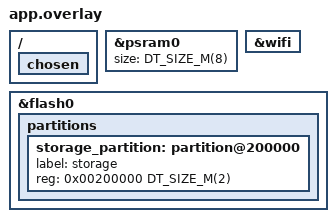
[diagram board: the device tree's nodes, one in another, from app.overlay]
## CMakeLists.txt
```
# SPDX-License-Identifier: Apache-2.0
cmake_minimum_required(VERSION 3.20.0)

set(ENV{ZEPHYR_BASE} "/home/alan/zephyr-projects/zephyr")
find_package(Zephyr REQUIRED HINTS $ENV{ZEPHYR_BASE})
project(espirate)

# Web Dashboard Generator: converts web/index.html -> web_dashboard.h
set(WEB_HTML_FILE ${CMAKE_CURRENT_SOURCE_DIR}/web/index.html)
set(GEN_WEB_HEADER ${CMAKE_CURRENT_BINARY_DIR}/include/web_dashboard.h)
set(GEN_WEB_SCRIPT ${CMAKE_CURRENT_SOURCE_DIR}/scripts/generate_web_dashboard.py)

# Generate at CMake configure time if not already present or out of date
execute_process(
  COMMAND ${PYTHON_EXECUTABLE} ${GEN_WEB_SCRIPT} ${WEB_HTML_FILE} ${GEN_WEB_HEADER}
)

# Custom command to regenerate during build whenever web/index.html or the generator changes
add_custom_command(
  OUTPUT ${GEN_WEB_HEADER}
  COMMAND ${PYTHON_EXECUTABLE} ${GEN_WEB_SCRIPT} ${WEB_HTML_FILE} ${GEN_WEB_HEADER}
  DEPENDS ${WEB_HTML_FILE} ${GEN_WEB_SCRIPT}
  COMMENT "Generating web_dashboard.h from ${WEB_HTML_FILE}"
  VERBATIM
)

# Custom target ensuring header is generated before any target compiles
add_custom_target(generate_web_dashboard DEPENDS ${GEN_WEB_HEADER})
add_dependencies(app generate_web_dashboard)

# How-To Guide Documentation Generator: converts doc/howto.md -> howto_doc.h
set(DOC_HOWTO_FILE ${CMAKE_CURRENT_SOURCE_DIR}/doc/howto.md)
set(GEN_DOC_HEADER ${CMAKE_CURRENT_BINARY_DIR}/include/howto_doc.h)
set(GEN_DOC_SCRIPT ${CMAKE_CURRENT_SOURCE_DIR}/scripts/generate_doc_header.py)

# Generate at CMake configure time if not already present or out of date
execute_process(
  COMMAND ${PYTHON_EXECUTABLE} ${GEN_DOC_SCRIPT} ${DOC_HOWTO_FILE} ${GEN_DOC_HEADER}
)

# Custom command to regenerate during build whenever doc/howto.md or the generator changes
add_custom_command(
  OUTPUT ${GEN_DOC_HEADER}
  COMMAND ${PYTHON_EXECUTABLE} ${GEN_DOC_SCRIPT} ${DOC_HOWTO_FILE} ${GEN_DOC_HEADER}
  DEPENDS ${DOC_HOWTO_FILE} ${GEN_DOC_SCRIPT}
  COMMENT "Generating howto_doc.h from ${DOC_HOWTO_FILE}"
  VERBATIM
)

# Custom target ensuring header is generated before any target compiles
add_custom_target(generate_doc_header DEPENDS ${GEN_DOC_HEADER})
add_dependencies(app generate_doc_header)

# Favicon Image Generator: converts web/favicon.png -> favicon_image.h
set(WEB_FAVICON_FILE ${CMAKE_CURRENT_SOURCE_DIR}/web/favicon.png)
set(GEN_FAVICON_HEADER ${CMAKE_CURRENT_BINARY_DIR}/include/favicon_image.h)
set(GEN_FAVICON_SCRIPT ${CMAKE_CURRENT_SOURCE_DIR}/scripts/generate_favicon_header.py)

# Generate at CMake configure time if not already present or out of date
execute_process(
  COMMAND ${PYTHON_EXECUTABLE} ${GEN_FAVICON_SCRIPT} ${WEB_FAVICON_FILE} ${GEN_FAVICON_HEADER}
)

# Custom command to regenerate during build whenever web/favicon.png or the generator changes
add_custom_command(
  OUTPUT ${GEN_FAVICON_HEADER}
  COMMAND ${PYTHON_EXECUTABLE} ${GEN_FAVICON_SCRIPT} ${WEB_FAVICON_FILE} ${GEN_FAVICON_HEADER}
  DEPENDS ${WEB_FAVICON_FILE} ${GEN_FAVICON_SCRIPT}
  COMMENT "Generating favicon_image.h from ${WEB_FAVICON_FILE}"
  VERBATIM
)

# Custom target ensuring header is generated before any target compiles
add_custom_target(generate_favicon_header DEPENDS ${GEN_FAVICON_HEADER})
add_dependencies(app generate_favicon_header)

# Include directories
target_include_directories(app PRIVATE
  ${CMAKE_CURRENT_SOURCE_DIR}/src
  ${CMAKE_CURRENT_SOURCE_DIR}/lua
  ${CMAKE_CURRENT_BINARY_DIR}/include
)

# Lua Engine Sources
set(LUA_SOURCES
  lua/lapi.c
  lua/lauxlib.c
  lua/lbaselib.c
  lua/lcode.c
  lua/lcorolib.c
  lua/lctype.c
  lua/ldblib.c
  lua/ldebug.c
  lua/ldo.c
  lua/ldump.c
  lua/lfunc.c
  lua/lgc.c
  lua/linit.c
  lua/liolib.c
  lua/llex.c
  lua/lmathlib.c
  lua/lmem.c
  lua/loadlib.c
  lua/lobject.c
  lua/lopcodes.c
  lua/loslib.c
  lua/lparser.c
  lua/lstate.c
  lua/lstring.c
  lua/lstrlib.c
  lua/ltable.c
  lua/ltablib.c
  lua/ltm.c
  lua/lundump.c
  lua/lutf8lib.c
  lua/lvm.c
  lua/lzio.c
)

# ESPirate Application Sources
target_sources(app PRIVATE
  src/main.c
  src/shell_commands.c
  src/lua_manager.c
  src/lua_worker.c
  src/fs_manager.c
  src/lua_gpio.c
  src/hw_gpio.c
  src/hw_pwm.c
  src/hw_i2c.c
  src/hw_spi.c
  src/wifi_manager.c
  src/captive_dns.c
  src/web_server.c
  src/posix_stubs.c
  src/setjmp.S
  ${GEN_WEB_HEADER}
  ${GEN_DOC_HEADER}
  ${LUA_SOURCES}
)

# Link math library
target_link_libraries(app PUBLIC -lm)

# Allow multiple definitions for standard libc/posix wrapper symbols
target_link_options(app PUBLIC "-Wl,--allow-multiple-definition")
```

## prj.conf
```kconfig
# ESPirate Zephyr Configuration
# Target: ESP32-S3 (DevKitM / DevKitC)

# Kernel Settings
CONFIG_MAIN_STACK_SIZE=8192
CONFIG_HEAP_MEM_POOL_SIZE=65536
CONFIG_SYSTEM_WORKQUEUE_STACK_SIZE=4096

# FPU & Standard C Library for Lua
CONFIG_FPU=y
CONFIG_FPU_SHARING=y
CONFIG_PICOLIBC=y
CONFIG_CBPRINTF_FP_SUPPORT=y

# Console & Shell (UART0 over USB CP2102 Bridge)
CONFIG_SERIAL=y
CONFIG_CONSOLE=y
CONFIG_UART_CONSOLE=y
CONFIG_SHELL=y
CONFIG_SHELL_BACKEND_SERIAL=y
CONFIG_SHELL_PROMPT_UART="ESPirate> "
CONFIG_SHELL_STACK_SIZE=8192
CONFIG_SHELL_CMD_BUFF_SIZE=512
CONFIG_SHELL_PRINTF_BUFF_SIZE=512
CONFIG_SHELL_WILDCARD=n

# Hardware control & Utilities
CONFIG_GPIO=y
CONFIG_REBOOT=y
CONFIG_LOG=y
CONFIG_LOG_MODE_IMMEDIATE=y
CONFIG_LOG_DEFAULT_LEVEL=3

# Flash & LittleFS Storage Subsystem
CONFIG_FLASH=y
CONFIG_FLASH_MAP=y
CONFIG_SPI_FLASH_SUPPORT_BOYA_CHIP=y
CONFIG_FILE_SYSTEM=y
CONFIG_FILE_SYSTEM_LITTLEFS=y
CONFIG_FILE_SYSTEM_SHELL=y
CONFIG_FILE_SYSTEM_MKFS=y
CONFIG_FS_LITTLEFS_LOOKAHEAD_SIZE=128

# PSRAM Configuration (8MB Embedded Octal PSRAM)
CONFIG_ESP_SPIRAM=y
CONFIG_ESP_SPIRAM_SIZE=8388608
CONFIG_SPIRAM_MODE_OCT=y
CONFIG_SPIRAM_TYPE_ESPPSRAM64=y
CONFIG_SPIRAM_SPEED_80M=y
CONFIG_ESP_SPIRAM_HEAP_SIZE=4194304

# Networking & BSD Sockets
CONFIG_NETWORKING=y
CONFIG_NET_IPV4=y
CONFIG_NET_IPV4_IGMP=y
CONFIG_NET_TCP=y
CONFIG_NET_UDP=y
CONFIG_NET_SOCKETS=y
CONFIG_NET_L2_ETHERNET=y
CONFIG_NET_L2_WIFI_MGMT=y
CONFIG_NET_MGMT=y
CONFIG_NET_MGMT_EVENT=y
CONFIG_NET_MGMT_EVENT_INFO=y
CONFIG_NET_CONNECTION_MANAGER=y
CONFIG_NET_CONNECTION_MANAGER_MONITOR_STACK_SIZE=1024
CONFIG_NET_CONFIG_AUTO_INIT=n
CONFIG_NET_IF_MAX_IPV4_COUNT=2
CONFIG_NET_IF_UNICAST_IPV4_ADDR_COUNT=4
CONFIG_NET_IF_MCAST_IPV4_ADDR_COUNT=4
CONFIG_NET_INTERFACE_NAME=y
CONFIG_NET_MAX_CONTEXTS=32
CONFIG_NET_MAX_CONN=32
CONFIG_NET_PKT_RX_COUNT=64
CONFIG_NET_PKT_TX_COUNT=48
CONFIG_NET_BUF_RX_COUNT=160
CONFIG_NET_BUF_TX_COUNT=160
CONFIG_NET_BUF_DATA_SIZE=1280
CONFIG_NET_TCP_TIME_WAIT_DELAY=250
CONFIG_NET_CONTEXT_RCVTIMEO=y
CONFIG_NET_CONTEXT_SNDTIMEO=y
CONFIG_ZVFS_POLL_MAX=32
CONFIG_NET_SOCKETS_SERVICE_STACK_SIZE=4096
CONFIG_NET_SOCKETS_SERVICE_THREAD_PRIO=6
CONFIG_NET_MGMT_EVENT_QUEUE_SIZE=16
CONFIG_NET_MGMT_EVENT_QUEUE_TIMEOUT=500
CONFIG_NET_LOG=y
CONFIG_MDNS_RESPONDER_LOG_LEVEL_INF=y
CONFIG_MDNS_RESPONDER_TTL=15
CONFIG_NET_SHELL=y
CONFIG_NET_STATISTICS=y
CONFIG_NET_STATISTICS_USER_API=y
CONFIG_NET_STATISTICS_IPV4=y
CONFIG_NET_STATISTICS_UDP=y
CONFIG_NET_STATISTICS_TCP=y
CONFIG_NET_STATISTICS_DNS=y

# DHCPv4 Client & Server
CONFIG_NET_DHCPV4=y
CONFIG_NET_DHCPV4_SERVER=y
CONFIG_NET_DHCPV4_SERVER_OPTION_ROUTER=y
CONFIG_NET_DHCPV4_SERVER_OPTION_DNS_ADDRESS="192.168.4.1"
CONFIG_NET_DHCPV4_SERVER_ADDR_COUNT=32
CONFIG_NET_DHCPV4_SERVER_ICMP_PROBE_TIMEOUT=0
CONFIG_NET_DHCPV4_SERVER_ADDR_DECLINE_TIME=60
CONFIG_NET_DHCPV4_SERVER_ADDR_LEASE_TIME=3600
CONFIG_NET_DHCPV4_SERVER_NAK_UNRECOGNIZED_REQUESTS=y
CONFIG_NET_DHCPV4_SERVER_LOG_LEVEL_DBG=y

# Hostname & mDNS Responder
CONFIG_NET_HOSTNAME_ENABLE=y
CONFIG_NET_HOSTNAME="espirate"
CONFIG_NET_HOSTNAME_DYNAMIC=y
CONFIG_NET_HOSTNAME_MAX_LEN=32
CONFIG_MDNS_RESPONDER=y

# Wi-Fi Driver (Exclusive AP or STA Mode)
CONFIG_WIFI=y
CONFIG_WIFI_ESP32=y
CONFIG_ESP32_WIFI_STA_AUTO_DHCPV4=n
CONFIG_ESP_WIFI_HEAP_SPIRAM=y
CONFIG_ESP32_WIFI_NET_ALLOC_SPIRAM=y
CONFIG_ESP32_WIFI_STA_SCAN_ALL=y
CONFIG_ESP32_WIFI_ENABLE_WPA3_SAE=y
CONFIG_ESP32_WIFI_WPA3_COMPATIBLE=y
CONFIG_WIFI_LOG_LEVEL_INF=y
CONFIG_NET_DHCPV4_LOG_LEVEL_DBG=y
CONFIG_ESP32_WIFI_DEBUG_PRINT=y
CONFIG_SHELL_LOG_LEVEL_DBG=y
CONFIG_LOG_CMDS=y

# Hardware Entropy Source
CONFIG_ENTROPY_GENERATOR=y
CONFIG_ENTROPY_ESP32_RNG=y
```

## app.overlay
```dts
/*
 * Copyright (c) 2026 Alan Mimms / ESPirate
 * SPDX-License-Identifier: Apache-2.0
 */

/ {
    chosen {
    };
};

/* 8MB Embedded PSRAM */
&psram0 {
    status = "okay";
    size = <DT_SIZE_M(8)>;
};

/* ESP32-S3 Wi-Fi Controller */
&wifi {
    status = "okay";
};

/* LittleFS Storage Partition baseline: 0x200000 (2MB offset).
 * On 4MB chip: 2MB LittleFS (0x200000 - 0x400000).
 * On 8MB chip: 6MB LittleFS (0x200000 - 0x800000, dynamically expanded at runtime).
 * On 16MB chip: 14MB LittleFS (0x200000 - 0x1000000, dynamically expanded at runtime).
 */
/delete-node/ &storage_partition;
/delete-node/ &slot1_partition;
/delete-node/ &slot0_appcpu_partition;
/delete-node/ &slot1_appcpu_partition;
/delete-node/ &slot0_lpcore_partition;
/delete-node/ &slot1_lpcore_partition;
/delete-node/ &scratch_partition;
/delete-node/ &coredump_partition;

&flash0 {
    partitions {
        storage_partition: partition@200000 {
            label = "storage";
            reg = <0x00200000 DT_SIZE_M(2)>;
        };
    };
};
```

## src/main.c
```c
/*
 * Copyright (c) 2026 Alan Mimms / ESPirate
 * SPDX-License-Identifier: Apache-2.0
 */

#include <zephyr/kernel.h>
#include <zephyr/logging/log.h>
#include <zephyr/version.h>
#include "shell_commands.h"
#include "lua_manager.h"
#include "lua_worker.h"
#include "fs_manager.h"
#include "wifi_manager.h"
#include "captive_dns.h"
#include "web_server.h"

LOG_MODULE_REGISTER(main, LOG_LEVEL_INF);

int main(void)
{
    LOG_INF("==================================================");
    LOG_INF("  ESPirate - Hardware Sequencing Architecture");
    LOG_INF("  Wi-Fi Dual-Mode (AP+STA), mDNS & Web Dashboard");
    LOG_INF("  Zephyr Kernel: %s", KERNEL_VERSION_STRING);
    LOG_INF("==================================================");

    /* Initialize LittleFS flash storage */
    int ret = fs_manager_init();
    if (ret != 0) {
        LOG_ERR("Failed to initialize LittleFS storage: %d", ret);
    }

    /* Initialize Lua VM and hardware subsystems */
    ret = lua_manager_init();
    if (ret != 0) {
        LOG_ERR("Failed to initialize Lua manager: %d", ret);
    }

    /* Start isolated Lua worker thread */
    ret = lua_worker_init();
    if (ret != 0) {
        LOG_ERR("Failed to initialize Lua worker: %d", ret);
    }

    /* Initialize Wi-Fi AP, STA, and dynamic hostname */
    ret = wifi_manager_init();
    if (ret != 0) {
        LOG_ERR("Failed to initialize Wi-Fi manager: %d", ret);
    }

    /* Start captive DNS responder on port 53 */
    ret = captive_dns_init();
    if (ret != 0) {
        LOG_ERR("Failed to initialize Captive DNS: %d", ret);
    }

    /* Start HTTP web server on port 80 */
    ret = web_server_init();
    if (ret != 0) {
        LOG_ERR("Failed to initialize Web server: %d", ret);
    }

    espirate_shell_init();

    LOG_INF("ESPirate shell ready on UART console.");
    LOG_INF("Soft-AP Dashboard : http://%s", wifi_manager_get_ip());
    LOG_INF("mDNS Local URL    : http://%s", wifi_manager_get_mdns_domain());
    LOG_INF("Pretend Internet  : %s",
            wifi_manager_get_fake_internet() ? "ENABLED (Android 204 active)" : "DISABLED");
    LOG_INF("Type 'help' or 'lua \"print(\\'hello\\')\"' to begin.");

    while (1) {
        k_sleep(K_SECONDS(30));
        LOG_DBG("Heartbeat tick - system alive (uptime: %lld ms)", k_uptime_get());
    }

    return 0;
}
```

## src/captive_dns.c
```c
/*
 * Copyright (c) 2026 Alan Mimms / ESPirate
 * SPDX-License-Identifier: Apache-2.0
 */

#include <zephyr/kernel.h>
#include <zephyr/logging/log.h>
#include <zephyr/net/socket.h>
#include <string.h>
#include <stdint.h>
#include "captive_dns.h"

LOG_MODULE_REGISTER(captive_dns, LOG_LEVEL_INF);

#define DNS_PORT 53
#define DNS_BUF_SIZE 512

K_THREAD_STACK_DEFINE(dns_thread_stack, 3072);
static struct k_thread dns_thread_data;
static bool s_enabled = true;
static int s_dns_sock = -1;

void captive_dns_set_enabled(bool enable)
{
    s_enabled = enable;
    LOG_INF("Captive DNS %s", enable ? "ENABLED (Pretend Internet ON)" : "DISABLED");
}

bool captive_dns_is_enabled(void)
{
    return s_enabled;
}

static void dns_thread_fn(void *p1, void *p2, void *p3)
{
    ARG_UNUSED(p1);
    ARG_UNUSED(p2);
    ARG_UNUSED(p3);

    /* Allow network interfaces to initialize */
    k_sleep(K_MSEC(1200));

    s_dns_sock = zsock_socket(AF_INET, SOCK_DGRAM, IPPROTO_UDP);
    if (s_dns_sock < 0) {
        LOG_ERR("Failed to create DNS UDP socket: %d", errno);
        return;
    }

    struct sockaddr_in bind_addr = {
        .sin_family = AF_INET,
        .sin_port = htons(DNS_PORT),
        .sin_addr.s_addr = htonl(INADDR_ANY),
    };

    if (zsock_bind(s_dns_sock, (struct sockaddr *)&bind_addr, sizeof(bind_addr)) < 0) {
        LOG_ERR("Failed to bind DNS socket to port %d: %d", DNS_PORT, errno);
        zsock_close(s_dns_sock);
        s_dns_sock = -1;
        return;
    }

    LOG_INF("Captive DNS responder active on UDP port %d", DNS_PORT);

    static uint8_t req_buf[DNS_BUF_SIZE];
    static uint8_t resp_buf[DNS_BUF_SIZE];

    while (1) {
        struct sockaddr_in client_addr;
        socklen_t client_len = sizeof(client_addr);

        ssize_t len = zsock_recvfrom(s_dns_sock, req_buf, sizeof(req_buf), 0,
                                     (struct sockaddr *)&client_addr, &client_len);
        if (len < 12) {
            continue;
        }

        if (!s_enabled) {
            continue;
        }

        /* Verify standard query (QR == 0) */
        if ((req_buf[2] & 0x80) != 0) {
            continue; /* Not a query */
        }

        /* Locate question section end */
        size_t pos = 12;
        while (pos < (size_t)len && req_buf[pos] != 0) {
            pos += 1 + req_buf[pos];
        }
        pos += 1; /* Skip trailing null byte of QNAME */
        pos += 4; /* Skip QTYPE (2 bytes) and QCLASS (2 bytes) */

        if (pos > (size_t)len || pos + 16 > sizeof(resp_buf)) {
            continue;
        }

        /* Build Response Header */
        memcpy(resp_buf, req_buf, pos);
        resp_buf[2] = 0x81; /* QR=1 (response), AA=1, RD=1 */
        resp_buf[3] = 0x80; /* RA=1, RCODE=0 (no error) */
        resp_buf[4] = 0x00; resp_buf[5] = 0x01; /* QDCOUNT = 1 */
        resp_buf[6] = 0x00; resp_buf[7] = 0x01; /* ANCOUNT = 1 */
        resp_buf[8] = 0x00; resp_buf[9] = 0x00; /* NSCOUNT = 0 */
        resp_buf[10] = 0x00; resp_buf[11] = 0x00; /* ARCOUNT = 0 */

        /* Append Answer Section (pointing to QNAME at offset 12) */
        resp_buf[pos++] = 0xc0; /* Pointer label */
        resp_buf[pos++] = 0x0c; /* Offset 12 */
        resp_buf[pos++] = 0x00; resp_buf[pos++] = 0x01; /* Type A */
        resp_buf[pos++] = 0x00; resp_buf[pos++] = 0x01; /* Class IN */
        resp_buf[pos++] = 0x00; resp_buf[pos++] = 0x00;
        resp_buf[pos++] = 0x00; resp_buf[pos++] = 0x3c; /* TTL: 60s */
        resp_buf[pos++] = 0x00; resp_buf[pos++] = 0x04; /* Length: 4 bytes */

        /* Target IPv4 address: 192.168.4.1 */
        resp_buf[pos++] = 192;
        resp_buf[pos++] = 168;
        resp_buf[pos++] = 4;
        resp_buf[pos++] = 1;

        zsock_sendto(s_dns_sock, resp_buf, pos, 0,
                     (struct sockaddr *)&client_addr, client_len);
    }
}

int captive_dns_init(void)
{
    k_thread_create(&dns_thread_data,
                    dns_thread_stack,
                    K_THREAD_STACK_SIZEOF(dns_thread_stack),
                    dns_thread_fn,
                    NULL, NULL, NULL,
                    7, 0, K_NO_WAIT);
    k_thread_name_set(&dns_thread_data, "captive_dns");
    return 0;
}
```

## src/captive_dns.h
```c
/*
 * Copyright (c) 2026 Alan Mimms / ESPirate
 * SPDX-License-Identifier: Apache-2.0
 */

#ifndef ESPIRATE_CAPTIVE_DNS_H_
#define ESPIRATE_CAPTIVE_DNS_H_

#include <stdbool.h>

#ifdef __cplusplus
extern "C" {
#endif

/**
 * @brief Initialize and start the captive DNS responder thread on UDP port 53.
 * @return 0 on success, negative error code on failure.
 */
int captive_dns_init(void);

/**
 * @brief Enable or disable captive DNS resolution (pretend internet).
 * @param enable true to resolve all DNS queries to 192.168.4.1, false to drop queries.
 */
void captive_dns_set_enabled(bool enable);

/**
 * @brief Check if captive DNS is currently enabled.
 * @return true if enabled, false otherwise.
 */
bool captive_dns_is_enabled(void);

#ifdef __cplusplus
}
#endif

#endif /* ESPIRATE_CAPTIVE_DNS_H_ */
```

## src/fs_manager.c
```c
/*
 * Copyright (c) 2026 Alan Mimms / ESPirate
 * SPDX-License-Identifier: Apache-2.0
 */

#include <zephyr/kernel.h>
#include <zephyr/device.h>
#include <zephyr/fs/fs.h>
#include <zephyr/fs/littlefs.h>
#include <zephyr/storage/flash_map.h>
#include <zephyr/logging/log.h>
#include <string.h>

#include "fs_manager.h"
#include "howto_doc.h"
#include "web_dashboard.h"
#include "favicon_image.h"

LOG_MODULE_REGISTER(fs_manager, LOG_LEVEL_INF);

FS_LITTLEFS_DECLARE_DEFAULT_CONFIG(storage_data);

static struct fs_mount_t espirate_lfs_mount = {
    .type = FS_LITTLEFS,
    .fs_data = &storage_data,
    .storage_dev = (void *)DT_FIXED_PARTITION_ID(DT_NODELABEL(storage_partition)),
    .mnt_point = ESPIRATE_FS_MOUNT_POINT,
};

static bool is_mounted = false;

#include <esp_err.h>
#include <esp_flash.h>
#include <esp_flash_internal.h>

extern const struct flash_area default_flash_map[];
extern const int flash_map_entries;
extern const struct flash_area *flash_map;

static struct flash_area s_dynamic_flash_map[16];
static size_t s_detected_partition_size = 0;
static uint32_t s_detected_chip_size = 0;

static void normalize_path(const char *in, char *out, size_t out_size)
{
    if (in[0] == '/') {
        strncpy(out, in, out_size - 1);
    } else {
        snprintf(out, out_size, "%s/%s", ESPIRATE_FS_MOUNT_POINT, in);
    }
    out[out_size - 1] = '\0';
}

int fs_manager_restore_docs(void)
{
    if (!is_mounted) {
        return -ENODEV;
    }
    int rc = fs_manager_write_file(ESPIRATE_FS_MOUNT_POINT "/howto.md",
                                   ESPIRATE_HOWTO_MD, ESPIRATE_HOWTO_MD_LEN);
    if (rc == 0) {
        LOG_INF("Restored /lfs/howto.md (%zu bytes) from firmware image", (size_t)ESPIRATE_HOWTO_MD_LEN);
    } else {
        LOG_ERR("Failed to restore /lfs/howto.md: %d", rc);
    }
    return rc;
}

int fs_manager_restore_web(void)
{
    if (!is_mounted) {
        return -ENODEV;
    }
    int rc = fs_manager_write_file(ESPIRATE_FS_MOUNT_POINT "/index.html",
                                   ESPIRATE_DASHBOARD_HTML, ESPIRATE_DASHBOARD_HTML_LEN);
    if (rc == 0) {
        LOG_INF("Restored /lfs/index.html (%zu bytes) from firmware image", (size_t)ESPIRATE_DASHBOARD_HTML_LEN);
    } else {
        LOG_ERR("Failed to restore /lfs/index.html: %d", rc);
    }
    return rc;
}

int fs_manager_restore_favicon(void)
{
    if (!is_mounted) {
        return -ENODEV;
    }
    int rc = fs_manager_write_file(ESPIRATE_FS_MOUNT_POINT "/favicon.png",
                                   ESPIRATE_FAVICON_PNG, ESPIRATE_FAVICON_PNG_LEN);
    if (rc == 0) {
        LOG_INF("Restored /lfs/favicon.png (%zu bytes) from firmware image", (size_t)ESPIRATE_FAVICON_PNG_LEN);
    } else {
        LOG_ERR("Failed to restore /lfs/favicon.png: %d", rc);
    }
    return rc;
}

int fs_manager_restore_all(void)
{
    if (!is_mounted) {
        return -ENODEV;
    }
    int ret = 0;
    int rc = fs_manager_restore_docs();
    if (rc != 0) ret = rc;
    rc = fs_manager_restore_web();
    if (rc != 0) ret = rc;
    rc = fs_manager_restore_favicon();
    if (rc != 0) ret = rc;
    return ret;
}

void fs_manager_create_default_files(void)
{
    if (!is_mounted) {
        return;
    }

    /* Write default demo script if it doesn't exist yet */
    struct fs_dirent dirent;
    if (fs_stat(ESPIRATE_FS_MOUNT_POINT "/demo.lua", &dirent) != 0) {
        const char *demo_code =
            "-- ESPirate LittleFS Demo Script\n"
            "print('========================================')\n"
            "print('Hello from /lfs/demo.lua!')\n"
            "print('Executing from persistent flash storage')\n"
            "print('Uptime ms:', sys.uptime())\n"
            "for i = 1, 3 do\n"
            "    print('  Iteration', i, 'running...')\n"
            "    sys.sleep(50)\n"
            "end\n"
            "print('Demo completed successfully.')\n"
            "print('========================================')\n";
        fs_manager_write_file(ESPIRATE_FS_MOUNT_POINT "/demo.lua", demo_code, strlen(demo_code));
        LOG_INF("Created default /lfs/demo.lua");
    }

    /* Write default howto.md documentation if it doesn't exist or size differs */
    if (fs_stat(ESPIRATE_FS_MOUNT_POINT "/howto.md", &dirent) != 0 ||
        dirent.size != (size_t)ESPIRATE_HOWTO_MD_LEN) {
        fs_manager_restore_docs();
    }

    /* Write default index.html dashboard if it doesn't exist or size differs */
    if (fs_stat(ESPIRATE_FS_MOUNT_POINT "/index.html", &dirent) != 0 ||
        dirent.size != (size_t)ESPIRATE_DASHBOARD_HTML_LEN) {
        fs_manager_restore_web();
    }

    /* Write default favicon.png if it doesn't exist or size differs */
    if (fs_stat(ESPIRATE_FS_MOUNT_POINT "/favicon.png", &dirent) != 0 ||
        dirent.size != (size_t)ESPIRATE_FAVICON_PNG_LEN) {
        fs_manager_restore_favicon();
    }
}

int fs_manager_init(void)
{
    if (is_mounted) {
        return 0;
    }

    esp_err_t ferr = esp_flash_init_default_chip();
    if (ferr != 0) {
        LOG_WRN("esp_flash_init_default_chip returned %d", ferr);
    }

    /* Detect actual physical SPI Flash size (4MB, 8MB, 16MB, etc.) */
    uint32_t chip_size = 0;
    esp_err_t sz_err = esp_flash_get_physical_size(NULL, &chip_size);
    if (sz_err != ESP_OK || chip_size == 0) {
        /* Fallback: read JEDEC ID directly (e.g. 0x684018 -> 1 << 0x18 = 16MB) */
        uint32_t flash_id = 0;
        if (esp_flash_read_id(NULL, &flash_id) == ESP_OK && flash_id > 0) {
            uint8_t size_code = flash_id & 0xFF;
            if (size_code >= 0x14 && size_code <= 0x21) { /* 1MB to 32MB */
                chip_size = 1U << size_code;
                LOG_INF("Derived physical flash size from JEDEC ID 0x%06x: %u MB (%u bytes)",
                        flash_id, chip_size / (1024 * 1024), chip_size);
            }
        }
    }

    if (chip_size > 0) {
        s_detected_chip_size = chip_size;
        /* Crucial: Update esp_flash_default_chip->size so ESP-IDF allows operations across full flash */
        if (esp_flash_default_chip != NULL) {
            esp_flash_default_chip->size = chip_size;
        }
        LOG_INF("Detected physical SPI flash size: %u MB (%u bytes)",
                chip_size / (1024 * 1024), chip_size);

        if (flash_map_entries <= ARRAY_SIZE(s_dynamic_flash_map)) {
            memcpy(s_dynamic_flash_map, default_flash_map,
                   flash_map_entries * sizeof(struct flash_area));

            uint8_t storage_id = (uint8_t)DT_FIXED_PARTITION_ID(DT_NODELABEL(storage_partition));
            for (int i = 0; i < flash_map_entries; i++) {
                if (s_dynamic_flash_map[i].fa_id == storage_id) {
                    off_t start_off = s_dynamic_flash_map[i].fa_off;
                    if ((uint32_t)start_off < chip_size) {
                        size_t dynamic_size = chip_size - start_off;
                        s_dynamic_flash_map[i].fa_size = dynamic_size;
                        s_detected_partition_size = dynamic_size;
                        LOG_INF("Dynamically adapted storage_partition: offset=0x%lx, size=%u MB (%zu bytes)",
                                (unsigned long)start_off,
                                (unsigned int)(dynamic_size / (1024 * 1024)),
                                dynamic_size);
                    }
                    break;
                }
            }
            flash_map = s_dynamic_flash_map;
        }
    } else {
        LOG_WRN("Physical flash size detection returned %d, using static DTS partition size", sz_err);
    }

    int rc = fs_mount(&espirate_lfs_mount);
    if (rc < 0) {
        LOG_WRN("LittleFS mount failed (%d); formatting blank/corrupt storage partition...", rc);
#if defined(CONFIG_FILE_SYSTEM_MKFS)
        rc = fs_mkfs(FS_LITTLEFS, (uintptr_t)DT_FIXED_PARTITION_ID(DT_NODELABEL(storage_partition)), NULL, 0);
        if (rc < 0) {
            LOG_ERR("fs_mkfs failed: %d", rc);
            return rc;
        }
        rc = fs_mount(&espirate_lfs_mount);
        if (rc < 0) {
            LOG_ERR("Failed to mount LittleFS after formatting: %d", rc);
            return rc;
        }
        LOG_INF("LittleFS partition formatted and mounted at %s", ESPIRATE_FS_MOUNT_POINT);
#else
        return rc;
#endif
    } else {
        /* Check if existing mounted filesystem size matches detected physical partition */
        struct fs_statvfs stat;
        if (fs_statvfs(ESPIRATE_FS_MOUNT_POINT, &stat) == 0 && s_detected_partition_size > 0) {
            size_t mounted_bytes = (size_t)stat.f_blocks * stat.f_frsize;
            if (mounted_bytes != s_detected_partition_size) {
                LOG_WRN("Mounted LittleFS capacity (%zu bytes) != partition size (%zu bytes). Auto-reformatting to full capacity...",
                        mounted_bytes, s_detected_partition_size);
                fs_unmount(&espirate_lfs_mount);
#if defined(CONFIG_FILE_SYSTEM_MKFS)
                rc = fs_mkfs(FS_LITTLEFS, (uintptr_t)DT_FIXED_PARTITION_ID(DT_NODELABEL(storage_partition)), NULL, 0);
                if (rc == 0) {
                    rc = fs_mount(&espirate_lfs_mount);
                }
#endif
            }
        }
    }

    is_mounted = true;
    LOG_INF("LittleFS mounted successfully at %s", ESPIRATE_FS_MOUNT_POINT);

    fs_manager_create_default_files();
    return 0;
}

bool fs_manager_is_mounted(void)
{
    return is_mounted;
}

int fs_manager_format(void)
{
    int rc;
    if (is_mounted) {
        rc = fs_unmount(&espirate_lfs_mount);
        if (rc < 0) {
            LOG_WRN("fs_unmount returned %d", rc);
        }
        is_mounted = false;
    }

#if defined(CONFIG_FILE_SYSTEM_MKFS)
    rc = fs_mkfs(FS_LITTLEFS, (uintptr_t)DT_FIXED_PARTITION_ID(DT_NODELABEL(storage_partition)), NULL, 0);
    if (rc < 0) {
        LOG_ERR("fs_mkfs failed: %d", rc);
        return rc;
    }
#endif

    rc = fs_mount(&espirate_lfs_mount);
    if (rc < 0) {
        LOG_ERR("fs_mount after format failed: %d", rc);
        return rc;
    }

    is_mounted = true;
    LOG_INF("LittleFS formatted and remounted at %s", ESPIRATE_FS_MOUNT_POINT);

    fs_manager_create_default_files();
    return 0;
}

int fs_manager_statvfs(size_t *total_bytes, size_t *free_bytes)
{
    if (!is_mounted) {
        return -ENODEV;
    }

    struct fs_statvfs stat;
    int rc = fs_statvfs(ESPIRATE_FS_MOUNT_POINT, &stat);
    if (rc < 0) {
        LOG_ERR("fs_statvfs failed: %d", rc);
        return rc;
    }

    if (total_bytes) {
        *total_bytes = (size_t)stat.f_blocks * stat.f_frsize;
    }
    if (free_bytes) {
        *free_bytes = (size_t)stat.f_bfree * stat.f_frsize;
    }

    return 0;
}

int fs_manager_write_file(const char *path, const void *data, size_t len)
{
    if (!is_mounted) {
        return -ENODEV;
    }

    char full_path[160];
    normalize_path(path, full_path, sizeof(full_path));

    struct fs_file_t file;
    fs_file_t_init(&file);

    int rc = fs_open(&file, full_path, FS_O_CREATE | FS_O_WRITE | FS_O_TRUNC);
    if (rc < 0) {
        LOG_ERR("Failed to open %s for writing: %d", full_path, rc);
        return rc;
    }

    ssize_t written = fs_write(&file, data, len);
    fs_close(&file);

    if (written < 0) {
        LOG_ERR("Failed to write to %s: %d", full_path, (int)written);
        return (int)written;
    }

    return 0;
}

int fs_manager_read_file(const char *path, void *buf, size_t buf_size, size_t *bytes_read)
{
    if (!is_mounted) {
        return -ENODEV;
    }

    char full_path[160];
    normalize_path(path, full_path, sizeof(full_path));

    struct fs_file_t file;
    fs_file_t_init(&file);

    int rc = fs_open(&file, full_path, FS_O_READ);
    if (rc < 0) {
        LOG_ERR("Failed to open %s for reading: %d", full_path, rc);
        return rc;
    }

    ssize_t read_bytes = fs_read(&file, buf, buf_size);
    fs_close(&file);

    if (read_bytes < 0) {
        LOG_ERR("Failed to read from %s: %d", full_path, (int)read_bytes);
        return (int)read_bytes;
    }

    if (bytes_read) {
        *bytes_read = (size_t)read_bytes;
    }

    return 0;
}

int fs_manager_delete_file(const char *path)
{
    if (!is_mounted) {
        return -ENODEV;
    }

    char full_path[160];
    normalize_path(path, full_path, sizeof(full_path));

    int rc = fs_unlink(full_path);
    if (rc != 0) {
        LOG_ERR("Failed to unlink %s: %d", full_path, rc);
    }
    return rc;
}

int fs_manager_rename_file(const char *old_path, const char *new_path)
{
    if (!is_mounted) {
        return -ENODEV;
    }

    char old_full[160];
    char new_full[160];
    normalize_path(old_path, old_full, sizeof(old_full));
    normalize_path(new_path, new_full, sizeof(new_full));

    int rc = fs_rename(old_full, new_full);
    if (rc != 0) {
        LOG_ERR("Failed to rename %s to %s: %d", old_full, new_full, rc);
    }
    return rc;
}

int fs_manager_list_files(fs_file_info_t *files, size_t max_files, size_t *count)
{
    if (!is_mounted) {
        return -ENODEV;
    }

    struct fs_dir_t dir;
    fs_dir_t_init(&dir);

    int rc = fs_opendir(&dir, ESPIRATE_FS_MOUNT_POINT);
    if (rc != 0) {
        LOG_ERR("Failed to opendir %s: %d", ESPIRATE_FS_MOUNT_POINT, rc);
        return rc;
    }

    size_t n = 0;
    struct fs_dirent entry;
    while (fs_readdir(&dir, &entry) == 0 && entry.name[0] != 0) {
        if (entry.type == FS_DIR_ENTRY_FILE) {
            if (files && n < max_files) {
                strncpy(files[n].name, entry.name, sizeof(files[n].name) - 1);
                files[n].name[sizeof(files[n].name) - 1] = '\0';
                files[n].size = entry.size;
            }
            n++;
        }
    }
    fs_closedir(&dir);

    if (count) {
        *count = n;
    }
    return 0;
}

uint32_t fs_manager_get_chip_size(void)
{
    return s_detected_chip_size;
}

size_t fs_manager_get_partition_size(void)
{
    return s_detected_partition_size;
}
```

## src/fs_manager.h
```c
/*
 * Copyright (c) 2026 Alan Mimms / ESPirate
 * SPDX-License-Identifier: Apache-2.0
 */

#ifndef ESPIRATE_FS_MANAGER_H_
#define ESPIRATE_FS_MANAGER_H_

#include <stddef.h>
#include <stdbool.h>

#ifdef __cplusplus
extern "C" {
#endif

#define ESPIRATE_FS_MOUNT_POINT "/lfs"

typedef struct {
    char name[64];
    size_t size;
} fs_file_info_t;

/**
 * @brief Initialize and mount the LittleFS partition at /lfs.
 * If mounting fails (e.g. on fresh chip), auto-formats the partition.
 * @return 0 on success, negative error code on failure.
 */
int fs_manager_init(void);

/**
 * @brief Check if the LittleFS partition is currently mounted.
 * @return true if mounted, false otherwise.
 */
bool fs_manager_is_mounted(void);

/**
 * @brief Reformat the LittleFS partition and recreate default files.
 * @return 0 on success, negative error code on failure.
 */
int fs_manager_format(void);

/**
 * @brief Get filesystem capacity and free space statistics.
 * @param total_bytes Pointer to store total capacity in bytes.
 * @param free_bytes Pointer to store free space in bytes.
 * @return 0 on success, negative error code on failure.
 */
int fs_manager_statvfs(size_t *total_bytes, size_t *free_bytes);

/**
 * @brief Write data to a file in LittleFS.
 * @param path Full file path (e.g. "/lfs/test.lua").
 * @param data Buffer containing file content.
 * @param len Length of data in bytes.
 * @return 0 on success, negative error code on failure.
 */
int fs_manager_write_file(const char *path, const void *data, size_t len);

/**
 * @brief Read data from a file in LittleFS.
 * @param path Full file path.
 * @param buf Output buffer.
 * @param buf_size Size of output buffer.
 * @param bytes_read Pointer to store actual bytes read (optional).
 * @return 0 on success, negative error code on failure.
 */
int fs_manager_read_file(const char *path, void *buf, size_t buf_size, size_t *bytes_read);

/**
 * @brief Delete (unlink) a file in LittleFS.
 * @param path File path or filename (e.g. "test.lua" or "/lfs/test.lua").
 * @return 0 on success, negative error code on failure.
 */
int fs_manager_delete_file(const char *path);

/**
 * @brief Rename a file in LittleFS.
 * @param old_path Current path or filename.
 * @param new_path Target path or filename.
 * @return 0 on success, negative error code on failure.
 */
int fs_manager_rename_file(const char *old_path, const char *new_path);

/**
 * @brief List files in LittleFS mount point.
 * @param files Buffer to store file info structures (may be NULL if max_files is 0).
 * @param max_files Maximum number of entries to store.
 * @param count Pointer to receive actual total count found.
 * @return 0 on success, negative error code on failure.
 */
int fs_manager_list_files(fs_file_info_t *files, size_t max_files, size_t *count);

/**
 * @brief Ensure default system files exist (e.g. /lfs/demo.lua and /lfs/howto.md).
 */
void fs_manager_create_default_files(void);

/**
 * @brief Force restore /lfs/howto.md from compiled-in firmware documentation.
 * @return 0 on success, negative error code on failure.
 */
int fs_manager_restore_docs(void);

/**
 * @brief Force restore /lfs/index.html from compiled-in firmware dashboard.
 * @return 0 on success, negative error code on failure.
 */
int fs_manager_restore_web(void);

/**
 * @brief Force restore /lfs/favicon.png from compiled-in firmware image.
 * @return 0 on success, negative error code on failure.
 */
int fs_manager_restore_favicon(void);

/**
 * @brief Force restore all default files (demo.lua, howto.md, index.html, favicon.png).
 * @return 0 on success, negative error code on failure.
 */
int fs_manager_restore_all(void);

/**
 * @brief Get detected physical SPI flash chip size in bytes.
 * @return Detected physical size in bytes (e.g. 16777216 for 16MB), or 0 if undetected.
 */
uint32_t fs_manager_get_chip_size(void);

/**
 * @brief Get dynamically adapted LittleFS partition size in bytes.
 * @return Partition size in bytes, or 0 if undetected.
 */
size_t fs_manager_get_partition_size(void);

#ifdef __cplusplus
}
#endif

#endif /* ESPIRATE_FS_MANAGER_H_ */
```

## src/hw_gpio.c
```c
/*
 * Copyright (c) 2026 Alan Mimms / ESPirate
 * SPDX-License-Identifier: Apache-2.0
 */

#include <zephyr/kernel.h>
#include <zephyr/device.h>
#include <zephyr/drivers/gpio.h>
#include <zephyr/logging/log.h>
#include <string.h>
#include <stdio.h>

#include <esp_rom_gpio.h>
#include <soc/gpio_sig_map.h>

#include "hw_gpio.h"

LOG_MODULE_REGISTER(hw_gpio, LOG_LEVEL_INF);

static const struct device *gpio0_dev = DEVICE_DT_GET(DT_NODELABEL(gpio0));
static const struct device *gpio1_dev = DEVICE_DT_GET(DT_NODELABEL(gpio1));

static gpio_flags_t s_pin_flags[49] = {0};
static int s_pin_out_sig[49] = {0};
static int s_pin_in_sig[49] = {0};

int hw_gpio_init(void)
{
    if (!device_is_ready(gpio0_dev)) {
        LOG_WRN("gpio0 device not ready");
    }
    if (!device_is_ready(gpio1_dev)) {
        LOG_WRN("gpio1 device not ready");
    }
    for (int i = 0; i < 49; i++) {
        s_pin_flags[i] = GPIO_DISCONNECTED;
        s_pin_out_sig[i] = SIG_GPIO_OUT_IDX;
        s_pin_in_sig[i] = -1;
    }
    return 0;
}

int hw_gpio_check_safety(int pin, const char **reason)
{
    if (pin < 0 || pin > 48) {
        if (reason) *reason = "out of range (0..48)";
        return -EINVAL;
    }
    if (pin >= 22 && pin <= 25) {
        if (reason) *reason = "not bonded on ESP32-S3 silicon";
        return -EINVAL;
    }
    if (pin == 19 || pin == 20) {
        if (reason) *reason = "reserved for native USB OTG console (CDC-ACM)";
        return -EPERM;
    }
    if (pin >= 26 && pin <= 32) {
        if (reason) *reason = "reserved for Octal SPI Flash/PSRAM bus";
        return -EPERM;
    }
    if (pin >= 33 && pin <= 37) {
        if (reason) *reason = "reserved for Octal PSRAM data lines";
        return -EPERM;
    }
    return 0;
}

static int get_gpio_port_and_pin(int pin, const struct device **dev_out, gpio_pin_t *pin_out)
{
    const char *reason = NULL;
    int ret = hw_gpio_check_safety(pin, &reason);
    if (ret != 0) {
        return ret;
    }
    if (pin < 32) {
        *dev_out = gpio0_dev;
        *pin_out = (gpio_pin_t)pin;
    } else {
        *dev_out = gpio1_dev;
        *pin_out = (gpio_pin_t)(pin - 32);
    }
    if (!device_is_ready(*dev_out)) {
        return -ENODEV;
    }
    return 0;
}

int hw_gpio_mode(int pin, const char *mode, const char *pull)
{
    if (!mode) return -EINVAL;

    const struct device *dev;
    gpio_pin_t pin_idx;
    int ret = get_gpio_port_and_pin(pin, &dev, &pin_idx);
    if (ret != 0) return ret;

    gpio_flags_t flags = GPIO_DISCONNECTED;
    if (strcmp(mode, "out") == 0 || strcmp(mode, "output") == 0) {
        flags = GPIO_OUTPUT | GPIO_INPUT;
    } else if (strcmp(mode, "in") == 0 || strcmp(mode, "input") == 0) {
        flags = GPIO_INPUT;
    } else if (strcmp(mode, "in_pullup") == 0 || strcmp(mode, "pullup") == 0) {
        flags = GPIO_INPUT | GPIO_PULL_UP;
    } else if (strcmp(mode, "in_pulldown") == 0 || strcmp(mode, "pulldown") == 0) {
        flags = GPIO_INPUT | GPIO_PULL_DOWN;
    } else if (strcmp(mode, "out_pullup") == 0) {
        flags = GPIO_OUTPUT | GPIO_INPUT | GPIO_PULL_UP;
    } else if (strcmp(mode, "out_pulldown") == 0) {
        flags = GPIO_OUTPUT | GPIO_INPUT | GPIO_PULL_DOWN;
    } else if (strcmp(mode, "open_drain") == 0 || strcmp(mode, "od") == 0) {
        flags = GPIO_OUTPUT | GPIO_INPUT | GPIO_OPEN_DRAIN;
    } else if (strcmp(mode, "open_drain_pullup") == 0 || strcmp(mode, "od_pullup") == 0) {
        flags = GPIO_OUTPUT | GPIO_INPUT | GPIO_OPEN_DRAIN | GPIO_PULL_UP;
    } else if (strcmp(mode, "tristate") == 0 || strcmp(mode, "hiz") == 0 ||
               strcmp(mode, "hi_z") == 0 || strcmp(mode, "disconnected") == 0 ||
               strcmp(mode, "none") == 0) {
        flags = GPIO_DISCONNECTED;
    } else {
        return -EINVAL;
    }

    if (pull) {
        flags &= ~(GPIO_PULL_UP | GPIO_PULL_DOWN);
        if (strcmp(pull, "up") == 0 || strcmp(pull, "pullup") == 0) {
            flags |= GPIO_PULL_UP;
        } else if (strcmp(pull, "down") == 0 || strcmp(pull, "pulldown") == 0) {
            flags |= GPIO_PULL_DOWN;
        } else if (strcmp(pull, "none") == 0 || strcmp(pull, "floating") == 0 || strcmp(pull, "off") == 0) {
            /* clear pulls */
        } else {
            return -EINVAL;
        }
    }

    esp_rom_gpio_pad_select_gpio((uint32_t)pin);
    ret = gpio_pin_configure(dev, pin_idx, flags);
    if (ret != 0) return ret;

    s_pin_flags[pin] = flags;
    return 0;
}

int hw_gpio_pull(int pin, const char *pull)
{
    if (!pull) return -EINVAL;

    const struct device *dev;
    gpio_pin_t pin_idx;
    int ret = get_gpio_port_and_pin(pin, &dev, &pin_idx);
    if (ret != 0) return ret;

    gpio_flags_t flags = s_pin_flags[pin];
    if (flags == GPIO_DISCONNECTED && (flags & (GPIO_INPUT | GPIO_OUTPUT)) == 0) {
        flags = GPIO_INPUT;
    }

    flags &= ~(GPIO_PULL_UP | GPIO_PULL_DOWN);
    if (strcmp(pull, "up") == 0 || strcmp(pull, "pullup") == 0) {
        flags |= GPIO_PULL_UP;
    } else if (strcmp(pull, "down") == 0 || strcmp(pull, "pulldown") == 0) {
        flags |= GPIO_PULL_DOWN;
    } else if (strcmp(pull, "none") == 0 || strcmp(pull, "floating") == 0 || strcmp(pull, "off") == 0) {
        /* clear pulls */
    } else {
        return -EINVAL;
    }

    ret = gpio_pin_configure(dev, pin_idx, flags);
    if (ret != 0) return ret;

    s_pin_flags[pin] = flags;
    return 0;
}

int hw_gpio_tristate(int pin)
{
    const struct device *dev;
    gpio_pin_t pin_idx;
    int ret = get_gpio_port_and_pin(pin, &dev, &pin_idx);
    if (ret != 0) return ret;

    esp_rom_gpio_pad_select_gpio((uint32_t)pin);
    ret = gpio_pin_configure(dev, pin_idx, GPIO_DISCONNECTED);
    if (ret != 0) return ret;

    s_pin_flags[pin] = GPIO_DISCONNECTED;
    return 0;
}

int hw_gpio_write(int pin, int val)
{
    const struct device *dev;
    gpio_pin_t pin_idx;
    int ret = get_gpio_port_and_pin(pin, &dev, &pin_idx);
    if (ret != 0) return ret;

    /* Ensure output mode if currently disconnected */
    if ((s_pin_flags[pin] & GPIO_OUTPUT) == 0) {
        hw_gpio_mode(pin, "out", NULL);
    }

    return gpio_pin_set(dev, pin_idx, val ? 1 : 0);
}

int hw_gpio_read(int pin)
{
    const struct device *dev;
    gpio_pin_t pin_idx;
    int ret = get_gpio_port_and_pin(pin, &dev, &pin_idx);
    if (ret != 0) return ret;

    /* Ensure input buffer is active if currently disconnected */
    if ((s_pin_flags[pin] & GPIO_INPUT) == 0) {
        hw_gpio_mode(pin, "in", NULL);
    }

    return gpio_pin_get(dev, pin_idx);
}

int hw_gpio_toggle(int pin)
{
    const struct device *dev;
    gpio_pin_t pin_idx;
    int ret = get_gpio_port_and_pin(pin, &dev, &pin_idx);
    if (ret != 0) return ret;

    if ((s_pin_flags[pin] & GPIO_OUTPUT) == 0) {
        hw_gpio_mode(pin, "out", NULL);
    }

    return gpio_pin_toggle(dev, pin_idx);
}

int hw_gpio_high(int pin)
{
    return hw_gpio_write(pin, 1);
}

int hw_gpio_low(int pin)
{
    return hw_gpio_write(pin, 0);
}

int hw_gpio_drive(int pin, int ma)
{
    const char *reason = NULL;
    int ret = hw_gpio_check_safety(pin, &reason);
    if (ret != 0) return ret;

    uint32_t drv = 2; /* default 20mA */
    if (ma == 5 || ma == 0) drv = 0;
    else if (ma == 10 || ma == 1) drv = 1;
    else if (ma == 20 || ma == 2) drv = 2;
    else if (ma == 40 || ma == 3) drv = 3;
    else return -EINVAL;

    esp_rom_gpio_pad_set_drv((uint32_t)pin, drv);
    return 0;
}

int hw_gpio_get_info(int pin, hw_gpio_info_t *info)
{
    if (!info || pin < 0 || pin > 48) return -EINVAL;

    info->pin = pin;
    info->valid = (pin < 22 || pin > 25);
    info->reserved = (!info->valid || pin == 19 || pin == 20 || (pin >= 26 && pin <= 37));
    info->input = (info->valid && !info->reserved);
    info->output = (info->valid && !info->reserved);
    info->pullup = (info->valid && !info->reserved);
    info->pulldown = (info->valid && !info->reserved);

    static char adc_buf[16];
    if (pin >= 1 && pin <= 10) {
        snprintf(adc_buf, sizeof(adc_buf), "ADC1_CH%d", pin - 1);
        info->adc_name = adc_buf;
        info->analog = !info->reserved;
    } else if (pin >= 11 && pin <= 20) {
        snprintf(adc_buf, sizeof(adc_buf), "ADC2_CH%d", pin - 11);
        info->adc_name = adc_buf;
        info->analog = !info->reserved;
    } else {
        info->adc_name = NULL;
        info->analog = false;
    }

    if (!info->valid) {
        info->desc = "Not bonded on ESP32-S3 silicon";
    } else if (pin == 0) {
        info->desc = "Strapping Pin (BOOT button)";
    } else if (pin == 19) {
        info->desc = "Reserved: Native USB OTG D- (Console)";
    } else if (pin == 20) {
        info->desc = "Reserved: Native USB OTG D+ (Console)";
    } else if (pin >= 26 && pin <= 32) {
        info->desc = "Reserved: Octal SPI Flash / PSRAM";
    } else if (pin >= 33 && pin <= 37) {
        info->desc = "Reserved: Octal PSRAM data lines";
    } else if (pin == 43) {
        info->desc = "UART0 TXD (Console UART)";
    } else if (pin == 44) {
        info->desc = "UART0 RXD (Console UART)";
    } else if (pin == 45) {
        info->desc = "Strapping Pin (VDD_SPI voltage)";
    } else if (pin == 46) {
        info->desc = "Strapping Pin (Boot Mode / ROM log)";
    } else {
        info->desc = "General Purpose I/O";
    }

    return 0;
}

int hw_gpio_get_state(int pin, char *mode_buf, size_t mode_size, int *level)
{
    const char *reason = NULL;
    int ret = hw_gpio_check_safety(pin, &reason);
    if (ret != 0) {
        if (mode_buf && mode_size > 0) {
            snprintf(mode_buf, mode_size, "RESERVED (%s)", reason ? reason : "unsafe");
        }
        if (level) *level = -1;
        return ret;
    }

    gpio_flags_t flags = s_pin_flags[pin];
    const char *dir_str = "TRISTATE";
    if (flags & GPIO_OPEN_DRAIN) {
        dir_str = "OPEN_DRAIN";
    } else if ((flags & (GPIO_OUTPUT | GPIO_INPUT)) == (GPIO_OUTPUT | GPIO_INPUT)) {
        dir_str = "OUT (PUSH_PULL)";
    } else if (flags & GPIO_OUTPUT) {
        dir_str = "OUTPUT";
    } else if (flags & GPIO_INPUT) {
        dir_str = "INPUT";
    }

    const char *pull_str = "FLOATING";
    if (flags & GPIO_PULL_UP) {
        pull_str = "PULLUP";
    } else if (flags & GPIO_PULL_DOWN) {
        pull_str = "PULLDOWN";
    }

    if (mode_buf && mode_size > 0) {
        if (s_pin_out_sig[pin] != SIG_GPIO_OUT_IDX) {
            snprintf(mode_buf, mode_size, "%s [%s] -> Matrix(Sig %d: %s)",
                     dir_str, pull_str, s_pin_out_sig[pin],
                     hw_matrix_get_signal_name(s_pin_out_sig[pin]));
        } else {
            snprintf(mode_buf, mode_size, "%s [%s]", dir_str, pull_str);
        }
    }

    if (level) {
        const struct device *dev;
        gpio_pin_t pin_idx;
        if (get_gpio_port_and_pin(pin, &dev, &pin_idx) == 0) {
            *level = gpio_pin_get(dev, pin_idx);
        } else {
            *level = -1;
        }
    }
    return 0;
}

int hw_matrix_route_out(int pin, int sig_idx, bool out_inv, bool oen_inv)
{
    const char *reason = NULL;
    int ret = hw_gpio_check_safety(pin, &reason);
    if (ret != 0) return ret;

    esp_rom_gpio_pad_select_gpio((uint32_t)pin);
    esp_rom_gpio_connect_out_signal((uint32_t)pin, (uint32_t)sig_idx, out_inv, oen_inv);
    s_pin_out_sig[pin] = sig_idx;
    return 0;
}

int hw_matrix_route_in(int pin, int sig_idx, bool inv)
{
    const char *reason = NULL;
    int ret = hw_gpio_check_safety(pin, &reason);
    if (ret != 0) return ret;

    esp_rom_gpio_pad_select_gpio((uint32_t)pin);
    esp_rom_gpio_connect_in_signal((uint32_t)pin, (uint32_t)sig_idx, inv);
    s_pin_in_sig[pin] = sig_idx;
    return 0;
}

int hw_matrix_detach(int pin)
{
    const char *reason = NULL;
    int ret = hw_gpio_check_safety(pin, &reason);
    if (ret != 0) return ret;

    esp_rom_gpio_connect_out_signal((uint32_t)pin, SIG_GPIO_OUT_IDX, false, false);
    s_pin_out_sig[pin] = SIG_GPIO_OUT_IDX;
    s_pin_in_sig[pin] = -1;
    return 0;
}

const char *hw_matrix_get_signal_name(int sig_idx)
{
    switch (sig_idx) {
        case SIG_GPIO_OUT_IDX:          return "GPIO_OUT (Default)";
        case U0TXD_OUT_IDX:             return "U0TXD (UART0 Console TX)";
        case U1TXD_OUT_IDX:             return "U1TXD (UART1 TX)";
        case U2TXD_OUT_IDX:             return "U2TXD (UART2 TX)";
        case I2CEXT0_SCL_OUT_IDX:       return "I2C0_SCL (I2C0 Clock)";
        case I2CEXT0_SDA_OUT_IDX:       return "I2C0_SDA (I2C0 Data)";
        case I2CEXT1_SCL_OUT_IDX:       return "I2C1_SCL (I2C1 Clock)";
        case I2CEXT1_SDA_OUT_IDX:       return "I2C1_SDA (I2C1 Data)";
        case FSPICLK_OUT_IDX:           return "FSPICLK (SPI2 Clock)";
        case FSPID_OUT_IDX:             return "FSPID (SPI2 MOSI)";
        case FSPICS0_OUT_IDX:           return "FSPICS0 (SPI2 CS0)";
        case LEDC_LS_SIG_OUT0_IDX:      return "LEDC_OUT0 (PWM Channel 0)";
        case LEDC_LS_SIG_OUT1_IDX:      return "LEDC_OUT1 (PWM Channel 1)";
        case LEDC_LS_SIG_OUT2_IDX:      return "LEDC_OUT2 (PWM Channel 2)";
        case LEDC_LS_SIG_OUT3_IDX:      return "LEDC_OUT3 (PWM Channel 3)";
        case LEDC_LS_SIG_OUT4_IDX:      return "LEDC_OUT4 (PWM Channel 4)";
        case LEDC_LS_SIG_OUT5_IDX:      return "LEDC_OUT5 (PWM Channel 5)";
        case LEDC_LS_SIG_OUT6_IDX:      return "LEDC_OUT6 (PWM Channel 6)";
        case LEDC_LS_SIG_OUT7_IDX:      return "LEDC_OUT7 (PWM Channel 7)";
        default:                        return "UNKNOWN";
    }
}
```

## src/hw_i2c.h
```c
/*
 * Copyright (c) 2026 Alan Mimms / ESPirate
 * SPDX-License-Identifier: Apache-2.0
 */

#ifndef ESPIRATE_HW_I2C_H_
#define ESPIRATE_HW_I2C_H_

#include <stdint.h>
#include <stdbool.h>
#include <stddef.h>

#ifdef __cplusplus
extern "C" {
#endif

typedef struct {
    int scl_pin;
    int sda_pin;
    uint32_t speed_khz;
    bool active;
    uint8_t last_scanned_count;
    uint8_t last_scanned_addrs[128];
} hw_i2c_status_t;

/**
 * @brief Initialize/Configure the I2C bus pins and speed.
 */
int hw_i2c_init_bus(int scl_pin, int sda_pin, uint32_t speed_khz);

/**
 * @brief Perform a 7-bit address bus scan (0x08..0x77).
 * @param scl_pin SCL GPIO pin.
 * @param sda_pin SDA GPIO pin.
 * @param found_addrs Buffer to receive detected 7-bit addresses.
 * @param max_addrs Max entries in found_addrs.
 * @param count Output pointer to receive total detected count.
 * @return 0 on success, negative errno on failure.
 */
int hw_i2c_scan(int scl_pin, int sda_pin, uint8_t *found_addrs, size_t max_addrs, size_t *count);

/**
 * @brief Write bytes to an I2C device address.
 */
int hw_i2c_write(int scl_pin, int sda_pin, uint8_t addr, const uint8_t *buf, size_t len);

/**
 * @brief Read bytes from an I2C device address.
 */
int hw_i2c_read(int scl_pin, int sda_pin, uint8_t addr, uint8_t *buf, size_t len);

/**
 * @brief Write register/command bytes then read back response (repeated START).
 */
int hw_i2c_write_read(int scl_pin, int sda_pin, uint8_t addr,
                      const uint8_t *tx_buf, size_t tx_len,
                      uint8_t *rx_buf, size_t rx_len);

/**
 * @brief Query current I2C subsystem status.
 */
int hw_i2c_get_status(hw_i2c_status_t *status);

#ifdef __cplusplus
}
#endif

#endif /* ESPIRATE_HW_I2C_H_ */
```
